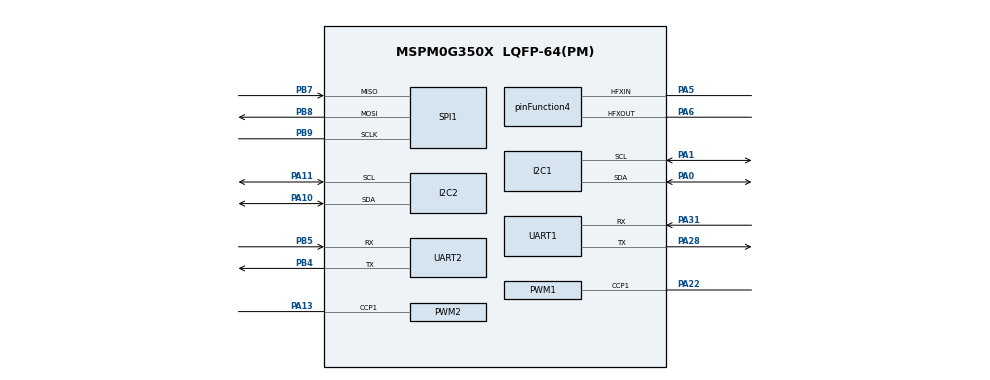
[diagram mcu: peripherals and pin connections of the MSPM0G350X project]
/**
 * @cliArgs --device "MSPM0G350X" --part "Default" --package "LQFP-64(PM)" --product "mspm0_sdk@2.05.01.01"
 * @versions {"tool":"1.21.1+3772"}
 */

/**
 * Import the modules used in this configuration.
 */
const GPIO    = scripting.addModule("/ti/driverlib/GPIO", {}, false);
const GPIO1   = GPIO.addInstance();
const GPIO2   = GPIO.addInstance();
const GPIO3   = GPIO.addInstance();
const GPIO4   = GPIO.addInstance();
const GPIO5   = GPIO.addInstance();
const I2C     = scripting.addModule("/ti/driverlib/I2C", {}, false);
const I2C1    = I2C.addInstance();
const I2C2    = I2C.addInstance();
const PWM     = scripting.addModule("/ti/driverlib/PWM", {}, false);
const PWM1    = PWM.addInstance();
const PWM2    = PWM.addInstance();
const SPI     = scripting.addModule("/ti/driverlib/SPI", {}, false);
const SPI1    = SPI.addInstance();
const SYSCTL  = scripting.addModule("/ti/driverlib/SYSCTL");
const SYSTICK = scripting.addModule("/ti/driverlib/SYSTICK");
const TIMER   = scripting.addModule("/ti/driverlib/TIMER", {}, false);
const TIMER1  = TIMER.addInstance();
const UART    = scripting.addModule("/ti/driverlib/UART", {}, false);
const UART1   = UART.addInstance();
const UART2   = UART.addInstance();

/**
 * Write custom configuration values to the imported modules.
 */
const divider9       = system.clockTree["UDIV"];
divider9.divideValue = 2;

const multiplier2         = system.clockTree["PLL_QDIV"];
multiplier2.multiplyValue = 4;

const mux4       = system.clockTree["EXHFMUX"];
mux4.inputSelect = "EXHFMUX_XTAL";

const mux8       = system.clockTree["HSCLKMUX"];
mux8.inputSelect = "HSCLKMUX_SYSPLL0";

const mux12       = system.clockTree["SYSPLLMUX"];
mux12.inputSelect = "zSYSPLLMUX_HFCLK";

const pinFunction4                        = system.clockTree["HFXT"];
pinFunction4.inputFreq                    = 40;
pinFunction4.enable                       = true;
pinFunction4.HFCLKMonitor                 = true;
pinFunction4.HFXTStartup                  = 10;
pinFunction4.peripheral.$assign           = "SYSCTL";
pinFunction4.peripheral.hfxInPin.$assign  = "PA5";
pinFunction4.peripheral.hfxOutPin.$assign = "PA6";

GPIO1.$name                              = "KEY";
GPIO1.associatedPins.create(4);
GPIO1.associatedPins[0].$name            = "PIN_K1";
GPIO1.associatedPins[0].direction        = "INPUT";
GPIO1.associatedPins[0].internalResistor = "PULL_UP";
GPIO1.associatedPins[0].assignedPort     = "PORTA";
GPIO1.associatedPins[0].assignedPin      = "7";
GPIO1.associatedPins[1].$name            = "PIN_K2";
GPIO1.associatedPins[1].direction        = "INPUT";
GPIO1.associatedPins[1].internalResistor = "PULL_UP";
GPIO1.associatedPins[1].assignedPort     = "PORTB";
GPIO1.associatedPins[1].assignedPin      = "10";
GPIO1.associatedPins[2].direction        = "INPUT";
GPIO1.associatedPins[2].$name            = "PIN_K3";
GPIO1.associatedPins[2].internalResistor = "PULL_UP";
GPIO1.associatedPins[2].assignedPort     = "PORTB";
GPIO1.associatedPins[2].assignedPin      = "11";
GPIO1.associatedPins[3].$name            = "PIN_K4";
GPIO1.associatedPins[3].direction        = "INPUT";
GPIO1.associatedPins[3].internalResistor = "PULL_UP";
GPIO1.associatedPins[3].assignedPort     = "PORTB";
GPIO1.associatedPins[3].assignedPin      = "14";

const Board = scripting.addModule("/ti/driverlib/Board", {}, false);

GPIO2.$name                          = "GPIO_CS";
GPIO2.associatedPins.create(2);
GPIO2.associatedPins[0].$name        = "PIN_CS1";
GPIO2.associatedPins[0].assignedPort = "PORTB";
GPIO2.associatedPins[0].assignedPin  = "6";
GPIO2.associatedPins[1].$name        = "PIN_CS2";
GPIO2.associatedPins[1].assignedPort = "PORTA";
GPIO2.associatedPins[1].assignedPin  = "12";

GPIO3.$name                               = "GPIO_ENCODER";
GPIO3.associatedPins.create(4);
GPIO3.associatedPins[0].$name             = "PIN_LA";
GPIO3.associatedPins[0].assignedPort      = "PORTA";
GPIO3.associatedPins[0].direction         = "INPUT";
GPIO3.associatedPins[0].interruptEn       = true;
GPIO3.associatedPins[0].polarity          = "RISE";
GPIO3.associatedPins[0].assignedPin       = "14";
GPIO3.associatedPins[0].interruptPriority = "1";
GPIO3.associatedPins[0].internalResistor  = "PULL_DOWN";
GPIO3.associatedPins[1].$name             = "PIN_LB";
GPIO3.associatedPins[1].assignedPort      = "PORTA";
GPIO3.associatedPins[1].direction         = "INPUT";
GPIO3.associatedPins[1].assignedPin       = "15";
GPIO3.associatedPins[1].internalResistor  = "PULL_DOWN";
GPIO3.associatedPins[2].$name             = "PIN_RA";
GPIO3.associatedPins[2].assignedPort      = "PORTA";
GPIO3.associatedPins[2].direction         = "INPUT";
GPIO3.associatedPins[2].interruptEn       = true;
GPIO3.associatedPins[2].polarity          = "RISE";
GPIO3.associatedPins[2].assignedPin       = "16";
GPIO3.associatedPins[2].interruptPriority = "1";
GPIO3.associatedPins[2].internalResistor  = "PULL_DOWN";
GPIO3.associatedPins[3].$name             = "PIN_RB";
GPIO3.associatedPins[3].direction         = "INPUT";
GPIO3.associatedPins[3].assignedPort      = "PORTA";
GPIO3.associatedPins[3].assignedPin       = "17";
GPIO3.associatedPins[3].internalResistor  = "PULL_DOWN";

GPIO4.$name                          = "GPIO_AIN";
GPIO4.associatedPins.create(2);
GPIO4.associatedPins[0].assignedPin  = "24";
GPIO4.associatedPins[0].assignedPort = "PORTB";
GPIO4.associatedPins[0].$name        = "PIN_AIN1";
GPIO4.associatedPins[1].assignedPort = "PORTB";
GPIO4.associatedPins[1].assignedPin  = "25";
GPIO4.associatedPins[1].$name        = "PIN_AIN2";

GPIO5.$name                          = "GPIO_BIN";
GPIO5.associatedPins.create(2);
GPIO5.associatedPins[0].assignedPort = "PORTA";
GPIO5.associatedPins[0].assignedPin  = "26";
GPIO5.associatedPins[0].$name        = "PIN_BIN1";
GPIO5.associatedPins[1].assignedPort = "PORTA";
GPIO5.associatedPins[1].assignedPin  = "27";
GPIO5.associatedPins[1].$name        = "PIN_BIN2";

I2C1.$name                             = "I2C_OLED";
I2C1.basicEnableController             = true;
I2C1.basicControllerStandardBusSpeed   = "Fast";
I2C1.peripheral.$assign                = "I2C0";
I2C1.peripheral.sdaPin.$assign         = "PA0";
I2C1.peripheral.sclPin.$assign         = "PA1";
I2C1.sdaPinConfig.$name                = "ti_driverlib_gpio_GPIOPinGeneric0";
I2C1.sdaPinConfig.hideOutputInversion  = scripting.forceWrite(false);
I2C1.sdaPinConfig.onlyInternalResistor = scripting.forceWrite(false);
I2C1.sdaPinConfig.passedPeripheralType = scripting.forceWrite("Digital");
I2C1.sclPinConfig.$name                = "ti_driverlib_gpio_GPIOPinGeneric1";
I2C1.sclPinConfig.hideOutputInversion  = scripting.forceWrite(false);
I2C1.sclPinConfig.onlyInternalResistor = scripting.forceWrite(false);
I2C1.sclPinConfig.passedPeripheralType = scripting.forceWrite("Digital");

I2C2.$name                             = "I2C_GRAY";
I2C2.basicEnableController             = true;
I2C2.peripheral.$assign                = "I2C1";
I2C2.peripheral.sdaPin.$assign         = "PA10";
I2C2.peripheral.sclPin.$assign         = "PA11";
I2C2.sdaPinConfig.hideOutputInversion  = scripting.forceWrite(false);
I2C2.sdaPinConfig.onlyInternalResistor = scripting.forceWrite(false);
I2C2.sdaPinConfig.passedPeripheralType = scripting.forceWrite("Digital");
I2C2.sdaPinConfig.$name                = "ti_driverlib_gpio_GPIOPinGeneric6";
I2C2.sclPinConfig.hideOutputInversion  = scripting.forceWrite(false);
I2C2.sclPinConfig.onlyInternalResistor = scripting.forceWrite(false);
I2C2.sclPinConfig.passedPeripheralType = scripting.forceWrite("Digital");
I2C2.sclPinConfig.$name                = "ti_driverlib_gpio_GPIOPinGeneric8";

PWM1.$name                              = "PWM_MOTOR_L";
PWM1.ccIndex                            = [1];
PWM1.timerStartTimer                    = true;
PWM1.pwmMode                            = "EDGE_ALIGN_UP";
PWM1.clockPrescale                      = 40;
PWM1.peripheral.$assign                 = "TIMG8";
PWM1.peripheral.ccp1Pin.$assign         = "PA22";
PWM1.ccp1PinConfig.$name                = "ti_driverlib_gpio_GPIOPinGeneric5";
PWM1.ccp1PinConfig.direction            = scripting.forceWrite("OUTPUT");
PWM1.ccp1PinConfig.hideOutputInversion  = scripting.forceWrite(false);
PWM1.ccp1PinConfig.onlyInternalResistor = scripting.forceWrite(false);
PWM1.ccp1PinConfig.passedPeripheralType = scripting.forceWrite("Digital");
PWM1.PWM_CHANNEL_1.$name                = "ti_driverlib_pwm_PWMTimerCC0";

PWM2.$name                      = "PWM_MOTOR_R";
PWM2.timerStartTimer            = true;
PWM2.pwmMode                    = "EDGE_ALIGN_UP";
PWM2.ccIndex                    = [1];
PWM2.clockPrescale              = 40;
PWM2.peripheral.$assign         = "TIMG0";
PWM2.peripheral.ccp1Pin.$assign = "PA13";
PWM2.ccp1PinConfig.$name        = "ti_driverlib_gpio_GPIOPinGeneric15";
PWM2.PWM_CHANNEL_1.$name        = "ti_driverlib_pwm_PWMTimerCC1";

SPI1.$name                              = "SPI_BMI";
SPI1.frameFormat                        = "MOTO3";
SPI1.polarity                           = "1";
SPI1.phase                              = "1";
SPI1.targetBitRate                      = 10000000;
SPI1.peripheral.$assign                 = "SPI1";
SPI1.peripheral.sclkPin.$assign         = "PB9";
SPI1.peripheral.mosiPin.$assign         = "PB8";
SPI1.peripheral.misoPin.$assign         = "PB7";
SPI1.sclkPinConfig.direction            = scripting.forceWrite("OUTPUT");
SPI1.sclkPinConfig.onlyInternalResistor = scripting.forceWrite(false);
SPI1.sclkPinConfig.passedPeripheralType = scripting.forceWrite("Digital");
SPI1.sclkPinConfig.$name                = "ti_driverlib_gpio_GPIOPinGeneric2";
SPI1.mosiPinConfig.direction            = scripting.forceWrite("OUTPUT");
SPI1.mosiPinConfig.hideOutputInversion  = scripting.forceWrite(false);
SPI1.mosiPinConfig.onlyInternalResistor = scripting.forceWrite(false);
SPI1.mosiPinConfig.passedPeripheralType = scripting.forceWrite("Digital");
SPI1.mosiPinConfig.$name                = "ti_driverlib_gpio_GPIOPinGeneric3";
SPI1.misoPinConfig.onlyInternalResistor = scripting.forceWrite(false);
SPI1.misoPinConfig.passedPeripheralType = scripting.forceWrite("Digital");
SPI1.misoPinConfig.$name                = "ti_driverlib_gpio_GPIOPinGeneric4";

SYSCTL.forceDefaultClkConfig = true;
SYSCTL.clockTreeEn           = true;
SYSCTL.validateClkStatus     = true;
scripting.suppress("For best practices when the CPUCLK is running at 32MHz and above, clear the flash status bit using DL_FlashCTL_executeClearStatus\\(\\) before executing any flash operation\\. Otherwise there may be false positives\\.", SYSCTL);

SYSTICK.period            = 80000;
SYSTICK.interruptPriority = "0";

TIMER1.$name              = "TIMER_TICK";
TIMER1.timerClkDiv        = 8;
TIMER1.timerClkPrescale   = 10;
TIMER1.timerPeriod        = "1 ms";
TIMER1.timerStartTimer    = true;
TIMER1.interrupts         = ["ZERO"];
TIMER1.interruptPriority  = "0";
TIMER1.timerMode          = "PERIODIC";
TIMER1.peripheral.$assign = "TIMA0";

UART1.$name                    = "UART_0";
UART1.targetBaudRate           = 115200;
UART1.enabledInterrupts        = ["RX"];
UART1.interruptPriority        = "1";
UART1.peripheral.$assign       = "UART0";
UART1.peripheral.rxPin.$assign = "PA31";
UART1.peripheral.txPin.$assign = "PA28";
UART1.txPinConfig.$name        = "ti_driverlib_gpio_GPIOPinGeneric9";
UART1.rxPinConfig.$name        = "ti_driverlib_gpio_GPIOPinGeneric10";

UART2.$name                    = "UART_1";
UART2.targetBaudRate           = 115200;
UART2.enabledInterrupts        = ["RX"];
UART2.peripheral.$assign       = "UART1";
UART2.peripheral.rxPin.$assign = "PB5";
UART2.peripheral.txPin.$assign = "PB4";
UART2.txPinConfig.$name        = "ti_driverlib_gpio_GPIOPinGeneric11";
UART2.rxPinConfig.$name        = "ti_driverlib_gpio_GPIOPinGeneric12";

/**
 * Pinmux solution for unlocked pins/peripherals. This ensures that minor changes to the automatic solver in a future
 * version of the tool will not impact the pinmux you originally saw.  These lines can be completely deleted in order to
 * re-solve from scratch.
 */
GPIO1.associatedPins[0].pin.$suggestSolution = "PA7";
GPIO1.associatedPins[1].pin.$suggestSolution = "PB10";
GPIO1.associatedPins[2].pin.$suggestSolution = "PB11";
GPIO1.associatedPins[3].pin.$suggestSolution = "PB14";
Board.peripheral.$suggestSolution            = "DEBUGSS";
Board.peripheral.swclkPin.$suggestSolution   = "PA20";
Board.peripheral.swdioPin.$suggestSolution   = "PA19";
GPIO2.associatedPins[0].pin.$suggestSolution = "PB6";
GPIO2.associatedPins[1].pin.$suggestSolution = "PA12";
GPIO3.associatedPins[0].pin.$suggestSolution = "PA14";
GPIO3.associatedPins[1].pin.$suggestSolution = "PA15";
GPIO3.associatedPins[2].pin.$suggestSolution = "PA16";
GPIO3.associatedPins[3].pin.$suggestSolution = "PA17";
GPIO4.associatedPins[0].pin.$suggestSolution = "PB24";
GPIO4.associatedPins[1].pin.$suggestSolution = "PB25";
GPIO5.associatedPins[0].pin.$suggestSolution = "PA26";
GPIO5.associatedPins[1].pin.$suggestSolution = "PA27";
